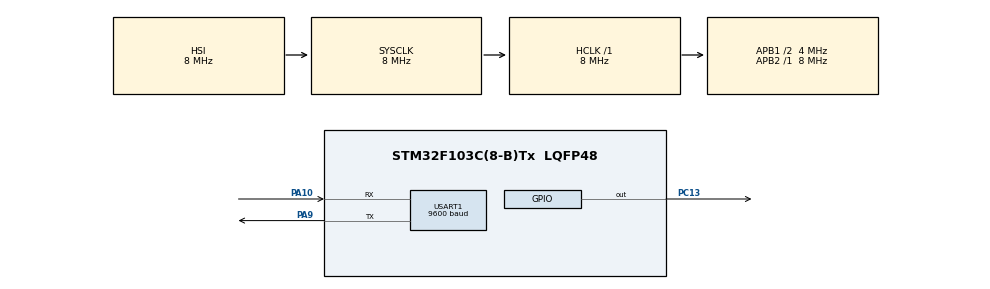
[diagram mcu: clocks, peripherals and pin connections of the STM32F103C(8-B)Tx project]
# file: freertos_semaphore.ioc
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FREERTOS.Tasks01=defaultTask,0,128,StartDefaultTask,Default,NULL,Dynamic,NULL,NULL
FREERTOS.configUSE_NEWLIB_REENTRANT=1
Mcu.Family=STM32F1
Mcu.Name=STM32F103C(8-B)Tx
Mcu.Package=LQFP48
NVIC.PriorityGroup=NVIC_PRIORITYGROUP_4
NVIC.TIM2_IRQn=true\:15\:0\:false\:false\:true\:false\:false\:true\:true
NVIC.TimeBase=TIM2_IRQn
NVIC.TimeBaseIP=TIM2
PA10.Mode=Asynchronous
PA10.Signal=USART1_RX
PA13.Mode=Serial_Wire
PA13.Signal=SYS_JTMS-SWDIO
PA14.Mode=Serial_Wire
PA14.Signal=SYS_JTCK-SWCLK
PA9.Mode=Asynchronous
PA9.Signal=USART1_TX
PC13-TAMPER-RTC.Signal=GPIO_Output
PC14-OSC32_IN.Mode=LSE-External-Oscillator
PC14-OSC32_IN.Signal=RCC_OSC32_IN
PC15-OSC32_OUT.Mode=LSE-External-Oscillator
PC15-OSC32_OUT.Signal=RCC_OSC32_OUT
PD0-OSC_IN.Mode=HSE-External-Oscillator
PD0-OSC_IN.Signal=RCC_OSC_IN
PD1-OSC_OUT.Mode=HSE-External-Oscillator
PD1-OSC_OUT.Signal=RCC_OSC_OUT
ProjectManager.HeapSize=0x200
ProjectManager.StackSize=0x400
ProjectManager.TargetToolchain=STM32CubeIDE
RCC.AHBFreq_Value=8000000
RCC.APB1CLKDivider=RCC_HCLK_DIV2
RCC.APB1Freq_Value=4000000
RCC.APB1TimFreq_Value=8000000
RCC.APB2Freq_Value=8000000
RCC.APB2TimFreq_Value=8000000
RCC.HCLKFreq_Value=8000000
RCC.PLLMUL=RCC_PLL_MUL9
RCC.PLLSourceVirtual=RCC_PLLSOURCE_HSE
RCC.SYSCLKFreq_VALUE=8000000
RCC.USBFreq_Value=72000000
USART1.BaudRate=9600
USART1.VirtualMode=VM_ASYNC
VP_FREERTOS_VS_CMSIS_V1.Mode=CMSIS_V1
VP_SYS_VS_tim2.Mode=TIM2
board=custom

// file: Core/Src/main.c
/* USER CODE BEGIN Header */
/**
  ******************************************************************************
  * @file           : main.c
  * @brief          : Main program body
  ******************************************************************************
  * @attention
  *
  * Copyright (c) 2023 STMicroelectronics.
  * All rights reserved.
  *
  * This software is licensed under terms that can be found in the LICENSE file
  * in the root directory of this software component.
  * If no LICENSE file comes with this software, it is provided AS-IS.
  *
  ******************************************************************************
  */
/* USER CODE END Header */
#include "main.h"
#include "cmsis_os.h"
#include "usart.h"
#include "gpio.h"
#include "semphr.h"
#include <string.h>

/* USER CODE BEGIN PV */
void sendtext( void *pvParameters );
void led_flash_task( void *pvParameters );

/* USER CODE END PV */

void SystemClock_Config(void);
void MX_FREERTOS_Init(void);
/* USER CODE BEGIN PFP */

void give_task(void* param);
void take_task(void* param);
/* USER CODE END PFP */

/* USER CODE BEGIN 0 */
SemaphoreHandle_t bin_sem_1;
/* USER CODE END 0 */

int main(void)
{
  /* USER CODE BEGIN 1 */
  TaskHandle_t xHandleLed = NULL;
  TaskHandle_t xHandleText = NULL;
  BaseType_t xReturned;

  bin_sem_1 = xSemaphoreCreateBinary();
  xSemaphoreGive(bin_sem_1);
  /* USER CODE END 1 */

  /* MCU Configuration--------------------------------------------------------*/

  /* Reset of all peripherals, Initializes the Flash interface and the Systick. */
  HAL_Init();

  /* Configure the system clock */
  SystemClock_Config();

  /* Initialize all configured peripherals */
  MX_GPIO_Init();
  MX_USART1_UART_Init();
  /* USER CODE BEGIN 2 */

  bin_sem_1 = xSemaphoreCreateBinary();
  xSemaphoreGive(bin_sem_1);

  xTaskCreate(give_task, ( signed portCHAR * ) "V", 256/* stack size */, NULL, tskIDLE_PRIORITY + 10, NULL );
  xTaskCreate(take_task, ( signed portCHAR * ) "P", 256/* stack size */, NULL, tskIDLE_PRIORITY + 10, NULL );

  /* Start running the tasks. */
  vTaskStartScheduler();

  /* USER CODE END 2 */

  /* We should never get here as control is now taken by the scheduler */
  /* Infinite loop */
  while (1)
  {

  }
}

void SystemClock_Config(void)
{
  RCC_OscInitTypeDef RCC_OscInitStruct = {0};
  RCC_ClkInitTypeDef RCC_ClkInitStruct = {0};

  /** Initializes the RCC Oscillators according to the specified parameters
  * in the RCC_OscInitTypeDef structure.
  */
  RCC_OscInitStruct.OscillatorType = RCC_OSCILLATORTYPE_HSI;
  RCC_OscInitStruct.HSIState = RCC_HSI_ON;
  RCC_OscInitStruct.HSICalibrationValue = RCC_HSICALIBRATION_DEFAULT;
  RCC_OscInitStruct.PLL.PLLState = RCC_PLL_NONE;
  if (HAL_RCC_OscConfig(&RCC_OscInitStruct) != HAL_OK)
  {
    Error_Handler();
  }

  /** Initializes the CPU, AHB and APB buses clocks
  */
  RCC_ClkInitStruct.ClockType = RCC_CLOCKTYPE_HCLK|RCC_CLOCKTYPE_SYSCLK
                              |RCC_CLOCKTYPE_PCLK1|RCC_CLOCKTYPE_PCLK2;
  RCC_ClkInitStruct.SYSCLKSource = RCC_SYSCLKSOURCE_HSI;
  RCC_ClkInitStruct.AHBCLKDivider = RCC_SYSCLK_DIV1;
  RCC_ClkInitStruct.APB1CLKDivider = RCC_HCLK_DIV2;
  RCC_ClkInitStruct.APB2CLKDivider = RCC_HCLK_DIV1;

  if (HAL_RCC_ClockConfig(&RCC_ClkInitStruct, FLASH_LATENCY_0) != HAL_OK)
  {
    Error_Handler();
  }
}

/* USER CODE BEGIN 4 */
void myprintf(char *msg)
{
	uint8_t message[35] = {'\0'};
	sprintf(message, msg);
	HAL_UART_Transmit(&huart1, message, sizeof(message), 100);
}

void give_task(void* param)
{
    while(1){
        xSemaphoreGive(bin_sem_1);
        myprintf("TASK1 give \r\n");
        vTaskDelay(200);
    }
}

void take_task(void* param)
{
    while(1){
        if ( xSemaphoreTake(bin_sem_1,20)){
            myprintf("TASK2 get bin_sem_1 \r\n");
        }
        else{
            myprintf("TASK2 not get bin_sem_1\r\n");
        }
        vTaskDelay(500);
    }
}

/* USER CODE END 4 */

void HAL_TIM_PeriodElapsedCallback(TIM_HandleTypeDef *htim)
{
  if (htim->Instance == TIM2) {
    HAL_IncTick();
  }
}

void Error_Handler(void)
{
  __disable_irq();
  while (1)
  {
  }
}
